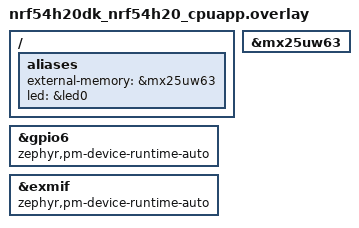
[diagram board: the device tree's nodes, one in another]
/*
 * Copyright (c) 2025 Nordic Semiconductor ASA
 *
 * SPDX-License-Identifier: LicenseRef-Nordic-5-Clause
 */

/ {
	aliases {
		external-memory = &mx25uw63;
		led = &led0;
		/delete-property/ led1;
	};
};

/delete-node/ &led1;

&gpio6 {
	status = "okay";
	zephyr,pm-device-runtime-auto;
};

&exmif {
	status = "okay";
	zephyr,pm-device-runtime-auto;
};

&mx25uw63 {
	status = "okay";
};
